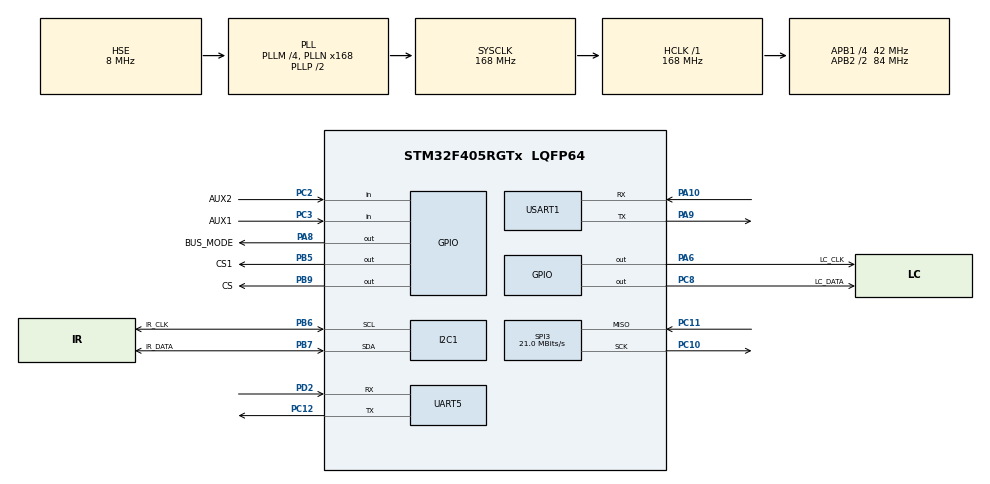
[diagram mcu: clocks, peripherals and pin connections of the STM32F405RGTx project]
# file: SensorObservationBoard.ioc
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FREERTOS.HEAP_NUMBER=4
FREERTOS.INCLUDE_eTaskGetState=0
FREERTOS.INCLUDE_pcTaskGetTaskName=0
FREERTOS.INCLUDE_uxTaskGetStackHighWaterMark=0
FREERTOS.INCLUDE_uxTaskGetStackHighWaterMark2=0
FREERTOS.INCLUDE_uxTaskPriorityGet=1
FREERTOS.INCLUDE_vTaskCleanUpResources=0
FREERTOS.INCLUDE_vTaskDelay=1
FREERTOS.INCLUDE_vTaskDelayUntil=1
FREERTOS.INCLUDE_vTaskDelete=1
FREERTOS.INCLUDE_vTaskPrioritySet=1
FREERTOS.INCLUDE_vTaskSuspend=1
FREERTOS.INCLUDE_xEventGroupSetBitFromISR=0
FREERTOS.INCLUDE_xQueueGetMutexHolder=0
FREERTOS.INCLUDE_xSemaphoreGetMutexHolder=0
FREERTOS.INCLUDE_xTaskAbortDelay=0
FREERTOS.INCLUDE_xTaskGetCurrentTaskHandle=0
FREERTOS.INCLUDE_xTaskGetHandle=0
FREERTOS.INCLUDE_xTaskResumeFromISR=1
FREERTOS.MEMORY_ALLOCATION=2
FREERTOS.Tasks01=defaultTask,0,128,StartDefaultTask,Default,NULL,Dynamic,NULL,NULL
FREERTOS.configCHECK_FOR_STACK_OVERFLOW=0
FREERTOS.configENABLE_BACKWARD_COMPATIBILITY=1
FREERTOS.configENABLE_FPU=0
FREERTOS.configGENERATE_RUN_TIME_STATS=0
FREERTOS.configIDLE_SHOULD_YIELD=1
FREERTOS.configLIBRARY_LOWEST_INTERRUPT_PRIORITY=15
FREERTOS.configLIBRARY_MAX_SYSCALL_INTERRUPT_PRIORITY=5
FREERTOS.configMAX_CO_ROUTINE_PRIORITIES=2
FREERTOS.configMAX_PRIORITIES=7
FREERTOS.configMAX_TASK_NAME_LEN=64
FREERTOS.configMINIMAL_STACK_SIZE=128
FREERTOS.configQUEUE_REGISTRY_SIZE=8
FREERTOS.configRECORD_STACK_HIGH_ADDRESS=0
FREERTOS.configTICK_RATE_HZ=1000
FREERTOS.configTOTAL_HEAP_SIZE=65536
FREERTOS.configUSE_APPLICATION_TASK_TAG=0
FREERTOS.configUSE_COUNTING_SEMAPHORES=0
FREERTOS.configUSE_CO_ROUTINES=0
FREERTOS.configUSE_DAEMON_TASK_STARTUP_HOOK=0
FREERTOS.configUSE_IDLE_HOOK=0
FREERTOS.configUSE_MALLOC_FAILED_HOOK=0
FREERTOS.configUSE_MUTEXES=1
FREERTOS.configUSE_NEWLIB_REENTRANT=1
FREERTOS.configUSE_POSIX_ERRNO=0
FREERTOS.configUSE_PREEMPTION=1
FREERTOS.configUSE_RECURSIVE_MUTEXES=0
FREERTOS.configUSE_STATS_FORMATTING_FUNCTIONS=0
FREERTOS.configUSE_TASK_NOTIFICATIONS=1
FREERTOS.configUSE_TICKLESS_IDLE=0
FREERTOS.configUSE_TICK_HOOK=0
FREERTOS.configUSE_TIMERS=0
FREERTOS.configUSE_TRACE_FACILITY=0
FREERTOS.copyHeapFile=1
Mcu.Family=STM32F4
Mcu.Name=STM32F405RGTx
Mcu.Package=LQFP64
NVIC.PriorityGroup=NVIC_PRIORITYGROUP_4
NVIC.TIM1_UP_TIM10_IRQn=true\:15\:0\:false\:false\:true\:false\:true\:true\:true
NVIC.TimeBase=TIM1_UP_TIM10_IRQn
NVIC.TimeBaseIP=TIM1
NVIC.UART5_IRQn=true\:5\:0\:false\:false\:true\:true\:true\:true\:true
NVIC.USART1_IRQn=true\:5\:0\:false\:false\:true\:true\:true\:true\:true
PA10.Mode=Asynchronous
PA10.Signal=USART1_RX
PA13.Mode=Trace_Asynchronous_SW
PA13.Signal=SYS_JTMS-SWDIO
PA14.Mode=Trace_Asynchronous_SW
PA14.Signal=SYS_JTCK-SWCLK
PA6.GPIO_Label=LC_CLK
PA6.Signal=GPIO_Output
PA8.GPIO_Label=BUS_MODE
PA8.GPIO_PuPd=GPIO_PULLUP
PA8.PinState=GPIO_PIN_SET
PA8.Signal=GPIO_Output
PA9.Mode=Asynchronous
PA9.Signal=USART1_TX
PB3.Mode=Trace_Asynchronous_SW
PB3.Signal=SYS_JTDO-SWO
PB5.GPIO_Label=CS1
PB5.GPIO_PuPd=GPIO_PULLUP
PB5.Signal=GPIO_Output
PB6.GPIO_Label=IR_CLK
PB6.Mode=I2C
PB6.Signal=I2C1_SCL
PB7.GPIO_Label=IR_DATA
PB7.Mode=I2C
PB7.Signal=I2C1_SDA
PB9.GPIO_Label=CS
PB9.Signal=GPIO_Output
PC10.Mode=RX_Only_Simplex_Unidirect_Master
PC10.Signal=SPI3_SCK
PC11.Mode=RX_Only_Simplex_Unidirect_Master
PC11.Signal=SPI3_MISO
PC12.Mode=Asynchronous
PC12.Signal=UART5_TX
PC2.GPIO_Label=AUX2
PC2.Signal=GPIO_Input
PC3.GPIO_Label=AUX1
PC3.Signal=GPIO_Input
PC8.GPIO_Label=LC_DATA
PC8.Signal=GPIO_Output
PD2.Mode=Asynchronous
PD2.Signal=UART5_RX
PH0-OSC_IN.Mode=HSE-External-Oscillator
PH0-OSC_IN.Signal=RCC_OSC_IN
PH1-OSC_OUT.Mode=HSE-External-Oscillator
PH1-OSC_OUT.Signal=RCC_OSC_OUT
ProjectManager.HeapSize=0x200
ProjectManager.StackSize=0x400
ProjectManager.TargetToolchain=STM32CubeIDE
RCC.48MHZClocksFreq_Value=84000000
RCC.AHBFreq_Value=168000000
RCC.APB1CLKDivider=RCC_HCLK_DIV4
RCC.APB1Freq_Value=42000000
RCC.APB1TimFreq_Value=84000000
RCC.APB2CLKDivider=RCC_HCLK_DIV2
RCC.APB2Freq_Value=84000000
RCC.APB2TimFreq_Value=168000000
RCC.CortexFreq_Value=168000000
RCC.HCLKFreq_Value=168000000
RCC.HSE_VALUE=8000000
RCC.HSI_VALUE=16000000
RCC.LSE_VALUE=32768
RCC.PLLM=4
RCC.PLLN=168
RCC.PLLSourceVirtual=RCC_PLLSOURCE_HSE
RCC.SYSCLKFreq_VALUE=168000000
RCC.SYSCLKSource=RCC_SYSCLKSOURCE_PLLCLK
RCC.VCOOutputFreq_Value=336000000
SPI3.BaudRatePrescaler=SPI_BAUDRATEPRESCALER_2
SPI3.CLKPhase=SPI_PHASE_1EDGE
SPI3.CalculateBaudRate=21.0 MBits/s
SPI3.Direction=SPI_DIRECTION_2LINES_RXONLY
SPI3.Mode=SPI_MODE_MASTER
SPI3.VirtualType=VM_MASTER
TIM2.AutoReloadPreload=TIM_AUTORELOAD_PRELOAD_ENABLE
TIM2.ClockDivision=TIM_CLOCKDIVISION_DIV1
TIM2.CounterMode=TIM_COUNTERMODE_UP
TIM2.Period=100
TIM2.Prescaler=105-1
TIM2.TIM_MasterOutputTrigger=TIM_TRGO_RESET
TIM2.TIM_MasterSlaveMode=TIM_MASTERSLAVEMODE_DISABLE
UART5.VirtualMode=Asynchronous
USART1.VirtualMode=VM_ASYNC
VP_CRC_VS_CRC.Mode=CRC_Activate
VP_FREERTOS_VS_CMSIS_V1.Mode=CMSIS_V1
VP_SYS_VS_tim1.Mode=TIM1
VP_TIM2_VS_ClockSourceINT.Mode=Internal
board=VanderAvionics

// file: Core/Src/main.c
/* USER CODE BEGIN Header */
/**
  ******************************************************************************
  * @file           : main.c
  * @brief          : Main program body
  ******************************************************************************
  * @attention
  *
  * Copyright (c) 2022 STMicroelectronics.
  * All rights reserved.
  *
  * This software is licensed under terms that can be found in the LICENSE file
  * in the root directory of this software component.
  * If no LICENSE file comes with this software, it is provided AS-IS.
  *
  ******************************************************************************
  */
/* USER CODE END Header */
#include "main.h"
#include "cmsis_os.h"

/* USER CODE BEGIN Includes */
#include "RunInterface.hpp"
/* USER CODE END Includes */

CRC_HandleTypeDef hcrc;

I2C_HandleTypeDef hi2c1;

SPI_HandleTypeDef hspi3;

TIM_HandleTypeDef htim2;

osThreadId defaultTaskHandle;
/* USER CODE BEGIN PV */
//DMA_HandleTypeDef& hdma_uart4_rx = SystemHandles::HAL::hdma_uart4_rx; //TODO: Add to SystemHandles::HAL
/* USER CODE END PV */

void SystemClock_Config(void);
static void MX_GPIO_Init(void);
static void MX_CRC_Init(void);
static void MX_TIM2_Init(void);
static void MX_USART1_UART_Init(void);
static void MX_I2C1_Init(void);
static void MX_UART5_Init(void);
static void MX_SPI3_Init(void);
void StartDefaultTask(void const * argument);

int main(void)
{

  /* MCU Configuration--------------------------------------------------------*/

  /* Reset of all peripherals, Initializes the Flash interface and the Systick. */
  HAL_Init();

  /* Configure the system clock */
  SystemClock_Config();

  /* Initialize all configured peripherals */
  MX_GPIO_Init();
  MX_CRC_Init();
  MX_TIM2_Init();
  MX_USART1_UART_Init();
  MX_I2C1_Init();
  MX_UART5_Init();
  MX_SPI3_Init();
  /* USER CODE BEGIN 2 */
  run_interface();
	#if 0
  /* USER CODE END 2 */

  /* Create the thread(s) */
  /* definition and creation of defaultTask */
  osThreadDef(defaultTask, StartDefaultTask, osPriorityNormal, 0, 128);
  defaultTaskHandle = osThreadCreate(osThread(defaultTask), NULL);

  /* Start scheduler */
  osKernelStart();

  /* We should never get here as control is now taken by the scheduler */
  /* Infinite loop */
  while (1)
  {

    /* USER CODE BEGIN 3 */
  }
#endif
  /* USER CODE END 3 */
}

void SystemClock_Config(void)
{
  RCC_OscInitTypeDef RCC_OscInitStruct = {0};
  RCC_ClkInitTypeDef RCC_ClkInitStruct = {0};

  /** Configure the main internal regulator output voltage
  */
  __HAL_RCC_PWR_CLK_ENABLE();
  __HAL_PWR_VOLTAGESCALING_CONFIG(PWR_REGULATOR_VOLTAGE_SCALE1);

  /** Initializes the RCC Oscillators according to the specified parameters
  * in the RCC_OscInitTypeDef structure.
  */
  RCC_OscInitStruct.OscillatorType = RCC_OSCILLATORTYPE_HSE;
  RCC_OscInitStruct.HSEState = RCC_HSE_ON;
  RCC_OscInitStruct.PLL.PLLState = RCC_PLL_ON;
  RCC_OscInitStruct.PLL.PLLSource = RCC_PLLSOURCE_HSE;
  RCC_OscInitStruct.PLL.PLLM = 4;
  RCC_OscInitStruct.PLL.PLLN = 168;
  RCC_OscInitStruct.PLL.PLLP = RCC_PLLP_DIV2;
  RCC_OscInitStruct.PLL.PLLQ = 4;
  if (HAL_RCC_OscConfig(&RCC_OscInitStruct) != HAL_OK)
  {
    Error_Handler();
  }

  /** Initializes the CPU, AHB and APB buses clocks
  */
  RCC_ClkInitStruct.ClockType = RCC_CLOCKTYPE_HCLK|RCC_CLOCKTYPE_SYSCLK
                              |RCC_CLOCKTYPE_PCLK1|RCC_CLOCKTYPE_PCLK2;
  RCC_ClkInitStruct.SYSCLKSource = RCC_SYSCLKSOURCE_PLLCLK;
  RCC_ClkInitStruct.AHBCLKDivider = RCC_SYSCLK_DIV1;
  RCC_ClkInitStruct.APB1CLKDivider = RCC_HCLK_DIV4;
  RCC_ClkInitStruct.APB2CLKDivider = RCC_HCLK_DIV2;

  if (HAL_RCC_ClockConfig(&RCC_ClkInitStruct, FLASH_LATENCY_5) != HAL_OK)
  {
    Error_Handler();
  }
}

static void MX_CRC_Init(void)
{

  hcrc.Instance = CRC;
  if (HAL_CRC_Init(&hcrc) != HAL_OK)
  {
    Error_Handler();
  }

}

static void MX_I2C1_Init(void)
{

  hi2c1.Instance = I2C1;
  hi2c1.Init.ClockSpeed = 100000;
  hi2c1.Init.DutyCycle = I2C_DUTYCYCLE_2;
  hi2c1.Init.OwnAddress1 = 0;
  hi2c1.Init.AddressingMode = I2C_ADDRESSINGMODE_7BIT;
  hi2c1.Init.DualAddressMode = I2C_DUALADDRESS_DISABLE;
  hi2c1.Init.OwnAddress2 = 0;
  hi2c1.Init.GeneralCallMode = I2C_GENERALCALL_DISABLE;
  hi2c1.Init.NoStretchMode = I2C_NOSTRETCH_DISABLE;
  if (HAL_I2C_Init(&hi2c1) != HAL_OK)
  {
    Error_Handler();
  }

}

static void MX_SPI3_Init(void)
{

  /* SPI3 parameter configuration*/
  hspi3.Instance = SPI3;
  hspi3.Init.Mode = SPI_MODE_MASTER;
  hspi3.Init.Direction = SPI_DIRECTION_2LINES_RXONLY;
  hspi3.Init.DataSize = SPI_DATASIZE_8BIT;
  hspi3.Init.CLKPolarity = SPI_POLARITY_LOW;
  hspi3.Init.CLKPhase = SPI_PHASE_1EDGE;
  hspi3.Init.NSS = SPI_NSS_SOFT;
  hspi3.Init.BaudRatePrescaler = SPI_BAUDRATEPRESCALER_2;
  hspi3.Init.FirstBit = SPI_FIRSTBIT_MSB;
  hspi3.Init.TIMode = SPI_TIMODE_DISABLE;
  hspi3.Init.CRCCalculation = SPI_CRCCALCULATION_DISABLE;
  hspi3.Init.CRCPolynomial = 10;
  if (HAL_SPI_Init(&hspi3) != HAL_OK)
  {
    Error_Handler();
  }

}

static void MX_TIM2_Init(void)
{

  TIM_ClockConfigTypeDef sClockSourceConfig = {0};
  TIM_MasterConfigTypeDef sMasterConfig = {0};

  htim2.Instance = TIM2;
  htim2.Init.Prescaler = 105-1;
  htim2.Init.CounterMode = TIM_COUNTERMODE_UP;
  htim2.Init.Period = 100;
  htim2.Init.ClockDivision = TIM_CLOCKDIVISION_DIV1;
  htim2.Init.AutoReloadPreload = TIM_AUTORELOAD_PRELOAD_ENABLE;
  if (HAL_TIM_Base_Init(&htim2) != HAL_OK)
  {
    Error_Handler();
  }
  sClockSourceConfig.ClockSource = TIM_CLOCKSOURCE_INTERNAL;
  if (HAL_TIM_ConfigClockSource(&htim2, &sClockSourceConfig) != HAL_OK)
  {
    Error_Handler();
  }
  sMasterConfig.MasterOutputTrigger = TIM_TRGO_RESET;
  sMasterConfig.MasterSlaveMode = TIM_MASTERSLAVEMODE_DISABLE;
  if (HAL_TIMEx_MasterConfigSynchronization(&htim2, &sMasterConfig) != HAL_OK)
  {
    Error_Handler();
  }

}

static void MX_UART5_Init(void)
{

  LL_USART_InitTypeDef USART_InitStruct = {0};

  LL_GPIO_InitTypeDef GPIO_InitStruct = {0};

  /* Peripheral clock enable */
  LL_APB1_GRP1_EnableClock(LL_APB1_GRP1_PERIPH_UART5);

  LL_AHB1_GRP1_EnableClock(LL_AHB1_GRP1_PERIPH_GPIOC);
  LL_AHB1_GRP1_EnableClock(LL_AHB1_GRP1_PERIPH_GPIOD);
  /**UART5 GPIO Configuration
  PC12   ------> UART5_TX
  PD2   ------> UART5_RX
  */
  GPIO_InitStruct.Pin = LL_GPIO_PIN_12;
  GPIO_InitStruct.Mode = LL_GPIO_MODE_ALTERNATE;
  GPIO_InitStruct.Speed = LL_GPIO_SPEED_FREQ_VERY_HIGH;
  GPIO_InitStruct.OutputType = LL_GPIO_OUTPUT_PUSHPULL;
  GPIO_InitStruct.Pull = LL_GPIO_PULL_NO;
  GPIO_InitStruct.Alternate = LL_GPIO_AF_8;
  LL_GPIO_Init(GPIOC, &GPIO_InitStruct);

  GPIO_InitStruct.Pin = LL_GPIO_PIN_2;
  GPIO_InitStruct.Mode = LL_GPIO_MODE_ALTERNATE;
  GPIO_InitStruct.Speed = LL_GPIO_SPEED_FREQ_VERY_HIGH;
  GPIO_InitStruct.OutputType = LL_GPIO_OUTPUT_PUSHPULL;
  GPIO_InitStruct.Pull = LL_GPIO_PULL_NO;
  GPIO_InitStruct.Alternate = LL_GPIO_AF_8;
  LL_GPIO_Init(GPIOD, &GPIO_InitStruct);

  /* UART5 interrupt Init */
  NVIC_SetPriority(UART5_IRQn, NVIC_EncodePriority(NVIC_GetPriorityGrouping(),5, 0));
  NVIC_EnableIRQ(UART5_IRQn);

  USART_InitStruct.BaudRate = 115200;
  USART_InitStruct.DataWidth = LL_USART_DATAWIDTH_8B;
  USART_InitStruct.StopBits = LL_USART_STOPBITS_1;
  USART_InitStruct.Parity = LL_USART_PARITY_NONE;
  USART_InitStruct.TransferDirection = LL_USART_DIRECTION_TX_RX;
  USART_InitStruct.HardwareFlowControl = LL_USART_HWCONTROL_NONE;
  USART_InitStruct.OverSampling = LL_USART_OVERSAMPLING_16;
  LL_USART_Init(UART5, &USART_InitStruct);
  LL_USART_ConfigAsyncMode(UART5);
  LL_USART_Enable(UART5);

}

static void MX_USART1_UART_Init(void)
{

  LL_USART_InitTypeDef USART_InitStruct = {0};

  LL_GPIO_InitTypeDef GPIO_InitStruct = {0};

  /* Peripheral clock enable */
  LL_APB2_GRP1_EnableClock(LL_APB2_GRP1_PERIPH_USART1);

  LL_AHB1_GRP1_EnableClock(LL_AHB1_GRP1_PERIPH_GPIOA);
  /**USART1 GPIO Configuration
  PA9   ------> USART1_TX
  PA10   ------> USART1_RX
  */
  GPIO_InitStruct.Pin = LL_GPIO_PIN_9|LL_GPIO_PIN_10;
  GPIO_InitStruct.Mode = LL_GPIO_MODE_ALTERNATE;
  GPIO_InitStruct.Speed = LL_GPIO_SPEED_FREQ_VERY_HIGH;
  GPIO_InitStruct.OutputType = LL_GPIO_OUTPUT_PUSHPULL;
  GPIO_InitStruct.Pull = LL_GPIO_PULL_NO;
  GPIO_InitStruct.Alternate = LL_GPIO_AF_7;
  LL_GPIO_Init(GPIOA, &GPIO_InitStruct);

  /* USART1 interrupt Init */
  NVIC_SetPriority(USART1_IRQn, NVIC_EncodePriority(NVIC_GetPriorityGrouping(),5, 0));
  NVIC_EnableIRQ(USART1_IRQn);

  USART_InitStruct.BaudRate = 115200;
  USART_InitStruct.DataWidth = LL_USART_DATAWIDTH_8B;
  USART_InitStruct.StopBits = LL_USART_STOPBITS_1;
  USART_InitStruct.Parity = LL_USART_PARITY_NONE;
  USART_InitStruct.TransferDirection = LL_USART_DIRECTION_TX_RX;
  USART_InitStruct.HardwareFlowControl = LL_USART_HWCONTROL_NONE;
  USART_InitStruct.OverSampling = LL_USART_OVERSAMPLING_16;
  LL_USART_Init(USART1, &USART_InitStruct);
  LL_USART_ConfigAsyncMode(USART1);
  LL_USART_Enable(USART1);

}

static void MX_GPIO_Init(void)
{
  GPIO_InitTypeDef GPIO_InitStruct = {0};

  /* GPIO Ports Clock Enable */
  __HAL_RCC_GPIOC_CLK_ENABLE();
  __HAL_RCC_GPIOH_CLK_ENABLE();
  __HAL_RCC_GPIOA_CLK_ENABLE();
  __HAL_RCC_GPIOB_CLK_ENABLE();
  __HAL_RCC_GPIOD_CLK_ENABLE();

  /*Configure GPIO pin Output Level */
  HAL_GPIO_WritePin(LC_CLK_GPIO_Port, LC_CLK_Pin, GPIO_PIN_RESET);

  /*Configure GPIO pin Output Level */
  HAL_GPIO_WritePin(LC_DATA_GPIO_Port, LC_DATA_Pin, GPIO_PIN_RESET);

  /*Configure GPIO pin Output Level */
  HAL_GPIO_WritePin(BUS_MODE_GPIO_Port, BUS_MODE_Pin, GPIO_PIN_SET);

  /*Configure GPIO pin Output Level */
  HAL_GPIO_WritePin(GPIOB, CS1_Pin|CS_Pin, GPIO_PIN_RESET);

  /*Configure GPIO pins : PC13 PC14 PC15 PC0
                           PC1 PC4 PC5 PC6
                           PC7 PC9 */
  GPIO_InitStruct.Pin = GPIO_PIN_13|GPIO_PIN_14|GPIO_PIN_15|GPIO_PIN_0
                          |GPIO_PIN_1|GPIO_PIN_4|GPIO_PIN_5|GPIO_PIN_6
                          |GPIO_PIN_7|GPIO_PIN_9;
  GPIO_InitStruct.Mode = GPIO_MODE_ANALOG;
  GPIO_InitStruct.Pull = GPIO_NOPULL;
  HAL_GPIO_Init(GPIOC, &GPIO_InitStruct);

  /*Configure GPIO pins : AUX2_Pin AUX1_Pin */
  GPIO_InitStruct.Pin = AUX2_Pin|AUX1_Pin;
  GPIO_InitStruct.Mode = GPIO_MODE_INPUT;
  GPIO_InitStruct.Pull = GPIO_NOPULL;
  HAL_GPIO_Init(GPIOC, &GPIO_InitStruct);

  /*Configure GPIO pins : PA0 PA1 PA2 PA3
                           PA4 PA5 PA7 PA11
                           PA12 PA15 */
  GPIO_InitStruct.Pin = GPIO_PIN_0|GPIO_PIN_1|GPIO_PIN_2|GPIO_PIN_3
                          |GPIO_PIN_4|GPIO_PIN_5|GPIO_PIN_7|GPIO_PIN_11
                          |GPIO_PIN_12|GPIO_PIN_15;
  GPIO_InitStruct.Mode = GPIO_MODE_ANALOG;
  GPIO_InitStruct.Pull = GPIO_NOPULL;
  HAL_GPIO_Init(GPIOA, &GPIO_InitStruct);

  /*Configure GPIO pin : LC_CLK_Pin */
  GPIO_InitStruct.Pin = LC_CLK_Pin;
  GPIO_InitStruct.Mode = GPIO_MODE_OUTPUT_PP;
  GPIO_InitStruct.Pull = GPIO_NOPULL;
  GPIO_InitStruct.Speed = GPIO_SPEED_FREQ_LOW;
  HAL_GPIO_Init(LC_CLK_GPIO_Port, &GPIO_InitStruct);

  /*Configure GPIO pins : PB0 PB1 PB2 PB10
                           PB11 PB12 PB13 PB14
                           PB15 PB4 PB8 */
  GPIO_InitStruct.Pin = GPIO_PIN_0|GPIO_PIN_1|GPIO_PIN_2|GPIO_PIN_10
                          |GPIO_PIN_11|GPIO_PIN_12|GPIO_PIN_13|GPIO_PIN_14
                          |GPIO_PIN_15|GPIO_PIN_4|GPIO_PIN_8;
  GPIO_InitStruct.Mode = GPIO_MODE_ANALOG;
  GPIO_InitStruct.Pull = GPIO_NOPULL;
  HAL_GPIO_Init(GPIOB, &GPIO_InitStruct);

  /*Configure GPIO pin : LC_DATA_Pin */
  GPIO_InitStruct.Pin = LC_DATA_Pin;
  GPIO_InitStruct.Mode = GPIO_MODE_OUTPUT_PP;
  GPIO_InitStruct.Pull = GPIO_NOPULL;
  GPIO_InitStruct.Speed = GPIO_SPEED_FREQ_LOW;
  HAL_GPIO_Init(LC_DATA_GPIO_Port, &GPIO_InitStruct);

  /*Configure GPIO pin : BUS_MODE_Pin */
  GPIO_InitStruct.Pin = BUS_MODE_Pin;
  GPIO_InitStruct.Mode = GPIO_MODE_OUTPUT_PP;
  GPIO_InitStruct.Pull = GPIO_PULLUP;
  GPIO_InitStruct.Speed = GPIO_SPEED_FREQ_LOW;
  HAL_GPIO_Init(BUS_MODE_GPIO_Port, &GPIO_InitStruct);

  /*Configure GPIO pin : CS1_Pin */
  GPIO_InitStruct.Pin = CS1_Pin;
  GPIO_InitStruct.Mode = GPIO_MODE_OUTPUT_PP;
  GPIO_InitStruct.Pull = GPIO_PULLUP;
  GPIO_InitStruct.Speed = GPIO_SPEED_FREQ_LOW;
  HAL_GPIO_Init(CS1_GPIO_Port, &GPIO_InitStruct);

  /*Configure GPIO pin : CS_Pin */
  GPIO_InitStruct.Pin = CS_Pin;
  GPIO_InitStruct.Mode = GPIO_MODE_OUTPUT_PP;
  GPIO_InitStruct.Pull = GPIO_NOPULL;
  GPIO_InitStruct.Speed = GPIO_SPEED_FREQ_LOW;
  HAL_GPIO_Init(CS_GPIO_Port, &GPIO_InitStruct);

}

void StartDefaultTask(void const * argument)
{
  for(;;)
  {
    osDelay(1);
  }
}

void HAL_TIM_PeriodElapsedCallback(TIM_HandleTypeDef *htim)
{
  if (htim->Instance == TIM1) {
    HAL_IncTick();
  }
}

void Error_Handler(void)
{
  __disable_irq();
  while (1)
  {
  }
}
